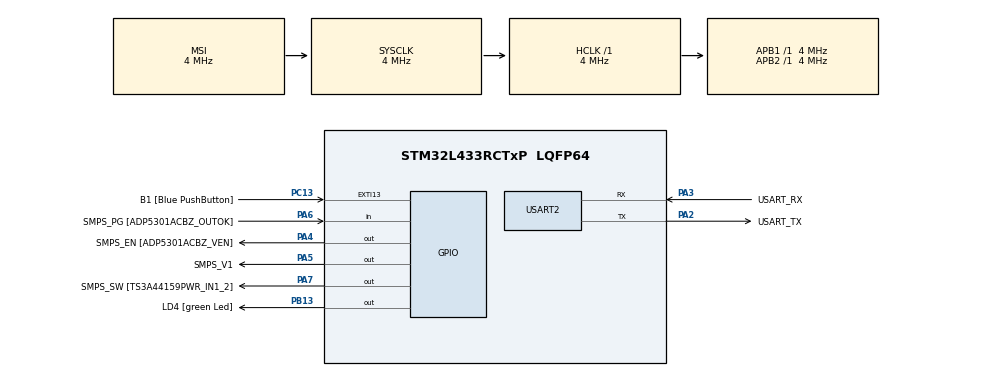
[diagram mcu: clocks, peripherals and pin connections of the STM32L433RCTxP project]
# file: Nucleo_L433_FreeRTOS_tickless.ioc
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FREERTOS.Tasks01=defaultTask,24,128,StartDefaultTask,Default,NULL,Dynamic,NULL,NULL
FREERTOS.configUSE_TICKLESS_IDLE=1
LPTIM1.ClockPrescaler=LPTIM_PRESCALER_DIV32
Mcu.Family=STM32L4
Mcu.Name=STM32L433RCTxP
Mcu.Package=LQFP64
NVIC.LPTIM1_IRQn=true\:5\:0\:false\:false\:true\:true\:true\:true\:true
NVIC.PriorityGroup=NVIC_PRIORITYGROUP_4
NVIC.TIM6_DAC_IRQn=true\:15\:0\:false\:false\:true\:false\:false\:true\:true
NVIC.TimeBase=TIM6_DAC_IRQn
NVIC.TimeBaseIP=TIM6
PA13\ (JTMS-SWDIO).GPIO_Label=TMS
PA13\ (JTMS-SWDIO).Mode=Serial_Wire
PA13\ (JTMS-SWDIO).Signal=SYS_JTMS-SWDIO
PA14\ (JTCK-SWCLK).GPIO_Label=TCK
PA14\ (JTCK-SWCLK).Mode=Serial_Wire
PA14\ (JTCK-SWCLK).Signal=SYS_JTCK-SWCLK
PA2.GPIO_Label=USART_TX
PA2.GPIO_Mode=GPIO_MODE_AF_PP
PA2.GPIO_PuPd=GPIO_NOPULL
PA2.GPIO_Speed=GPIO_SPEED_FREQ_VERY_HIGH
PA2.Mode=Asynchronous
PA2.Signal=USART2_TX
PA3.GPIO_Label=USART_RX
PA3.GPIO_Mode=GPIO_MODE_AF_PP
PA3.GPIO_PuPd=GPIO_NOPULL
PA3.GPIO_Speed=GPIO_SPEED_FREQ_VERY_HIGH
PA3.Mode=Asynchronous
PA3.Signal=USART2_RX
PA4.GPIO_Label=SMPS_EN [ADP5301ACBZ_VEN]
PA4.Signal=GPIO_Output
PA5.GPIO_Label=SMPS_V1
PA5.GPIO_ModeDefaultOutputPP=GPIO_MODE_OUTPUT_PP
PA5.GPIO_PuPd=GPIO_NOPULL
PA5.GPIO_Speed=GPIO_SPEED_FREQ_LOW
PA5.Signal=GPIO_Output
PA6.GPIO_Label=SMPS_PG [ADP5301ACBZ_OUTOK]
PA6.GPIO_PuPd=GPIO_PULLUP
PA6.Signal=GPIO_Input
PA7.GPIO_Label=SMPS_SW [TS3A44159PWR_IN1_2]
PA7.Signal=GPIO_Output
PB13.GPIO_Label=LD4 [green Led]
PB13.Signal=GPIO_Output
PB3\ (JTDO-TRACESWO).GPIO_Label=SWO
PB3\ (JTDO-TRACESWO).Signal=SYS_JTDO-SWO
PC13.GPIO_Label=B1 [Blue PushButton]
PC13.GPIO_ModeDefaultEXTI=GPIO_MODE_IT_FALLING
PC13.GPIO_PuPd=GPIO_NOPULL
PC13.Signal=GPXTI13
PC14-OSC32_IN\ (PC14).Mode=LSE-External-Oscillator
PC14-OSC32_IN\ (PC14).Signal=RCC_OSC32_IN
PC15-OSC32_OUT\ (PC15).Mode=LSE-External-Oscillator
PC15-OSC32_OUT\ (PC15).Signal=RCC_OSC32_OUT
PH0-OSC_IN\ (PH0).GPIO_Label=MCO
PH0-OSC_IN\ (PH0).Signal=RCC_OSC_IN
PH1-OSC_OUT\ (PH1).Signal=RCC_OSC_OUT
ProjectManager.HeapSize=0x200
ProjectManager.StackSize=0x400
ProjectManager.TargetToolchain=STM32CubeIDE
RCC.ADCFreq_Value=64000000
RCC.AHBFreq_Value=4000000
RCC.APB1Freq_Value=4000000
RCC.APB1TimFreq_Value=4000000
RCC.APB2Freq_Value=4000000
RCC.APB2TimFreq_Value=4000000
RCC.CortexFreq_Value=4000000
RCC.HCLKFreq_Value=4000000
RCC.HSE_VALUE=8000000
RCC.HSI48_VALUE=48000000
RCC.HSI_VALUE=16000000
RCC.LPTIM1CLockSelection=RCC_LPTIM1CLKSOURCE_LSE
RCC.MSI_VALUE=4000000
RCC.PLLN=10
RCC.PLLSourceVirtual=RCC_PLLSOURCE_HSI
RCC.PREFETCH_ENABLE=1
RCC.SYSCLKFreq_VALUE=4000000
RCC.USBFreq_Value=64000000
RCC.VCOOutputFreq_Value=160000000
USART2.VirtualMode-Asynchronous=VM_ASYNC
VP_FREERTOS_VS_CMSIS_V2.Mode=CMSIS_V2
VP_LPTIM1_VS_LPTIM_counterModeInternalClock.Mode=Counts__internal_clock_event_00
VP_SYS_VS_tim6.Mode=TIM6
board=NUCLEO-L433RC-P

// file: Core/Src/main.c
/* USER CODE BEGIN Header */
/**
  ******************************************************************************
  * @file           : main.c
  * @brief          : Main program body
  ******************************************************************************
  * @attention
  *
  * Copyright (c) 2023 STMicroelectronics.
  * All rights reserved.
  *
  * This software is licensed under terms that can be found in the LICENSE file
  * in the root directory of this software component.
  * If no LICENSE file comes with this software, it is provided AS-IS.
  *
  ******************************************************************************
  */
/* USER CODE END Header */
#include "main.h"
#include "cmsis_os.h"

LPTIM_HandleTypeDef hlptim1;

UART_HandleTypeDef huart2;

/* Definitions for defaultTask */
osThreadId_t defaultTaskHandle;
const osThreadAttr_t defaultTask_attributes = {
  .name = "defaultTask",
  .stack_size = 128 * 4,
  .priority = (osPriority_t) osPriorityNormal,
};

void SystemClock_Config(void);
static void MX_GPIO_Init(void);
static void MX_USART2_UART_Init(void);
static void MX_LPTIM1_Init(void);
void StartDefaultTask(void *argument);

int main(void)
{

  /* MCU Configuration--------------------------------------------------------*/

  /* Reset of all peripherals, Initializes the Flash interface and the Systick. */
  HAL_Init();

  /* Configure the system clock */
  SystemClock_Config();

  /* Initialize all configured peripherals */
  MX_GPIO_Init();
  MX_USART2_UART_Init();
  MX_LPTIM1_Init();

  /* Init scheduler */
  osKernelInitialize();

  /* Create the thread(s) */
  /* creation of defaultTask */
  defaultTaskHandle = osThreadNew(StartDefaultTask, NULL, &defaultTask_attributes);

  /* Start scheduler */
  osKernelStart();

  /* We should never get here as control is now taken by the scheduler */
  /* Infinite loop */
  while (1)
  {

  }
}

void SystemClock_Config(void)
{
  RCC_OscInitTypeDef RCC_OscInitStruct = {0};
  RCC_ClkInitTypeDef RCC_ClkInitStruct = {0};

  /** Configure the main internal regulator output voltage
  */
  if (HAL_PWREx_ControlVoltageScaling(PWR_REGULATOR_VOLTAGE_SCALE1) != HAL_OK)
  {
    Error_Handler();
  }

  /** Configure LSE Drive Capability
  */
  HAL_PWR_EnableBkUpAccess();
  __HAL_RCC_LSEDRIVE_CONFIG(RCC_LSEDRIVE_LOW);

  /** Initializes the RCC Oscillators according to the specified parameters
  * in the RCC_OscInitTypeDef structure.
  */
  RCC_OscInitStruct.OscillatorType = RCC_OSCILLATORTYPE_LSE|RCC_OSCILLATORTYPE_MSI;
  RCC_OscInitStruct.LSEState = RCC_LSE_ON;
  RCC_OscInitStruct.MSIState = RCC_MSI_ON;
  RCC_OscInitStruct.MSICalibrationValue = 0;
  RCC_OscInitStruct.MSIClockRange = RCC_MSIRANGE_6;
  RCC_OscInitStruct.PLL.PLLState = RCC_PLL_NONE;
  if (HAL_RCC_OscConfig(&RCC_OscInitStruct) != HAL_OK)
  {
    Error_Handler();
  }

  /** Initializes the CPU, AHB and APB buses clocks
  */
  RCC_ClkInitStruct.ClockType = RCC_CLOCKTYPE_HCLK|RCC_CLOCKTYPE_SYSCLK
                              |RCC_CLOCKTYPE_PCLK1|RCC_CLOCKTYPE_PCLK2;
  RCC_ClkInitStruct.SYSCLKSource = RCC_SYSCLKSOURCE_MSI;
  RCC_ClkInitStruct.AHBCLKDivider = RCC_SYSCLK_DIV1;
  RCC_ClkInitStruct.APB1CLKDivider = RCC_HCLK_DIV1;
  RCC_ClkInitStruct.APB2CLKDivider = RCC_HCLK_DIV1;

  if (HAL_RCC_ClockConfig(&RCC_ClkInitStruct, FLASH_LATENCY_0) != HAL_OK)
  {
    Error_Handler();
  }

  /** Enable MSI Auto calibration
  */
  HAL_RCCEx_EnableMSIPLLMode();
}

static void MX_LPTIM1_Init(void)
{

  hlptim1.Instance = LPTIM1;
  hlptim1.Init.Clock.Source = LPTIM_CLOCKSOURCE_APBCLOCK_LPOSC;
  hlptim1.Init.Clock.Prescaler = LPTIM_PRESCALER_DIV32;
  hlptim1.Init.Trigger.Source = LPTIM_TRIGSOURCE_SOFTWARE;
  hlptim1.Init.OutputPolarity = LPTIM_OUTPUTPOLARITY_HIGH;
  hlptim1.Init.UpdateMode = LPTIM_UPDATE_IMMEDIATE;
  hlptim1.Init.CounterSource = LPTIM_COUNTERSOURCE_INTERNAL;
  hlptim1.Init.Input1Source = LPTIM_INPUT1SOURCE_GPIO;
  hlptim1.Init.Input2Source = LPTIM_INPUT2SOURCE_GPIO;
  if (HAL_LPTIM_Init(&hlptim1) != HAL_OK)
  {
    Error_Handler();
  }

}

static void MX_USART2_UART_Init(void)
{

  huart2.Instance = USART2;
  huart2.Init.BaudRate = 115200;
  huart2.Init.WordLength = UART_WORDLENGTH_8B;
  huart2.Init.StopBits = UART_STOPBITS_1;
  huart2.Init.Parity = UART_PARITY_NONE;
  huart2.Init.Mode = UART_MODE_TX_RX;
  huart2.Init.HwFlowCtl = UART_HWCONTROL_NONE;
  huart2.Init.OverSampling = UART_OVERSAMPLING_16;
  huart2.Init.OneBitSampling = UART_ONE_BIT_SAMPLE_DISABLE;
  huart2.AdvancedInit.AdvFeatureInit = UART_ADVFEATURE_NO_INIT;
  if (HAL_UART_Init(&huart2) != HAL_OK)
  {
    Error_Handler();
  }

}

static void MX_GPIO_Init(void)
{
  GPIO_InitTypeDef GPIO_InitStruct = {0};

  /* GPIO Ports Clock Enable */
  __HAL_RCC_GPIOC_CLK_ENABLE();
  __HAL_RCC_GPIOH_CLK_ENABLE();
  __HAL_RCC_GPIOA_CLK_ENABLE();
  __HAL_RCC_GPIOB_CLK_ENABLE();

  /*Configure GPIO pin Output Level */
  HAL_GPIO_WritePin(GPIOA, SMPS_EN_Pin|SMPS_V1_Pin|SMPS_SW_Pin, GPIO_PIN_RESET);

  /*Configure GPIO pin Output Level */
  HAL_GPIO_WritePin(LD4_GPIO_Port, LD4_Pin, GPIO_PIN_RESET);

  /*Configure GPIO pin : B1_Pin */
  GPIO_InitStruct.Pin = B1_Pin;
  GPIO_InitStruct.Mode = GPIO_MODE_IT_FALLING;
  GPIO_InitStruct.Pull = GPIO_NOPULL;
  HAL_GPIO_Init(B1_GPIO_Port, &GPIO_InitStruct);

  /*Configure GPIO pins : SMPS_EN_Pin SMPS_V1_Pin SMPS_SW_Pin */
  GPIO_InitStruct.Pin = SMPS_EN_Pin|SMPS_V1_Pin|SMPS_SW_Pin;
  GPIO_InitStruct.Mode = GPIO_MODE_OUTPUT_PP;
  GPIO_InitStruct.Pull = GPIO_NOPULL;
  GPIO_InitStruct.Speed = GPIO_SPEED_FREQ_LOW;
  HAL_GPIO_Init(GPIOA, &GPIO_InitStruct);

  /*Configure GPIO pin : SMPS_PG_Pin */
  GPIO_InitStruct.Pin = SMPS_PG_Pin;
  GPIO_InitStruct.Mode = GPIO_MODE_INPUT;
  GPIO_InitStruct.Pull = GPIO_PULLUP;
  HAL_GPIO_Init(SMPS_PG_GPIO_Port, &GPIO_InitStruct);

  /*Configure GPIO pin : LD4_Pin */
  GPIO_InitStruct.Pin = LD4_Pin;
  GPIO_InitStruct.Mode = GPIO_MODE_OUTPUT_PP;
  GPIO_InitStruct.Pull = GPIO_NOPULL;
  GPIO_InitStruct.Speed = GPIO_SPEED_FREQ_LOW;
  HAL_GPIO_Init(LD4_GPIO_Port, &GPIO_InitStruct);

}

void StartDefaultTask(void *argument)
{
  /* USER CODE BEGIN 5 */
  /* Infinite loop */
  for(;;)
  {
	  HAL_GPIO_WritePin(LD4_GPIO_Port, LD4_Pin, GPIO_PIN_SET);
	  HAL_Delay(1000);
	  HAL_GPIO_WritePin(LD4_GPIO_Port, LD4_Pin, GPIO_PIN_RESET);
	  HAL_Delay(1000);
	  //Sleep
	  osDelay(5000);
  }
  /* USER CODE END 5 */
}

void HAL_TIM_PeriodElapsedCallback(TIM_HandleTypeDef *htim)
{
  if (htim->Instance == TIM6) {
    HAL_IncTick();
  }
}

void Error_Handler(void)
{
  __disable_irq();
  while (1)
  {
  }
}

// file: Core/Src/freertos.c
/* USER CODE BEGIN Header */
/**
  ******************************************************************************
  * File Name          : freertos.c
  * Description        : Code for freertos applications
  ******************************************************************************
  * @attention
  *
  * Copyright (c) 2023 STMicroelectronics.
  * All rights reserved.
  *
  * This software is licensed under terms that can be found in the LICENSE file
  * in the root directory of this software component.
  * If no LICENSE file comes with this software, it is provided AS-IS.
  *
  ******************************************************************************
  */
/* USER CODE END Header */

#include "FreeRTOS.h"
#include "task.h"
#include "main.h"

/* USER CODE BEGIN PD */
extern LPTIM_HandleTypeDef hlptim1;
/* USER CODE END PD */

/* USER CODE BEGIN PREPOSTSLEEP */
__weak void PreSleepProcessing(uint32_t ulExpectedIdleTime)
{
/* place for user code */
	HAL_SuspendTick();
	HAL_LPTIM_TimeOut_Start_IT(&hlptim1, 0xFFFF, ulExpectedIdleTime);
}

__weak void PostSleepProcessing(uint32_t ulExpectedIdleTime)
{
/* place for user code */
	HAL_LPTIM_TimeOut_Stop_IT(&hlptim1);
	HAL_ResumeTick();
}
/* USER CODE END PREPOSTSLEEP */
